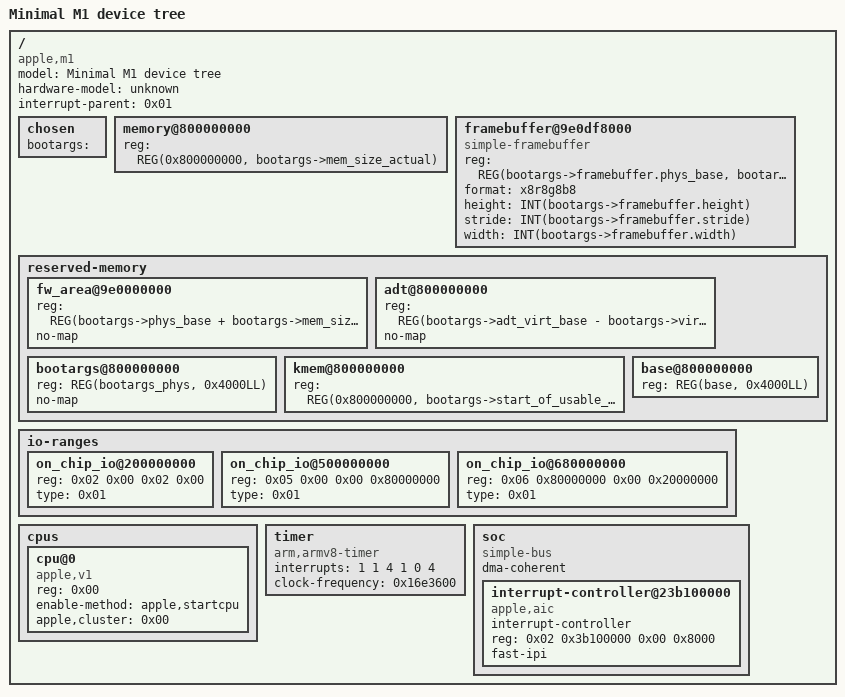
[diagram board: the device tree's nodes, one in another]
#define REG(x,y) <${cpu_to_be32((x)>>32)} \
	          ${cpu_to_be32((x)&U32_MAX)} \
		  ${cpu_to_be32((y)>>32)} \
		  ${cpu_to_be32((y)&U32_MAX)}>

#define INT(x) <${cpu_to_be32(x)}>

/dts-v1/;

/ {
	model = "Minimal M1 device tree";
	compatible = "apple,m1";
	hardware-model = "unknown";
	interrupt-parent = <0x01>;
	#address-cells = <0x02>;
	#size-cells = <0x02>;

	chosen {
		bootargs = "";
	};

	memory@800000000 {
		device_type = "memory";
		reg = REG(0x800000000, bootargs->mem_size_actual);
	};

	framebuffer@9e0df8000 {
		#address-cells = <0x02>;
		#size-cells = <0x02>;
		compatible = "simple-framebuffer";
		reg = REG(bootargs->framebuffer.phys_base,
		          bootargs->framebuffer.stride *
			  bootargs->framebuffer.height);
		format = "x8r8g8b8";
		height = INT(bootargs->framebuffer.height);
		stride = INT(bootargs->framebuffer.stride);
		width = INT(bootargs->framebuffer.width);
		status = "okay";
	};

	/* Technically, these areas shouldn't overlap. */
	reserved-memory {
		#address-cells = <0x02>;
		#size-cells = <0x02>;
		ranges;

		/* The area at the end of memory. Not actually at 9e0000000
		 * on most machines. */
		fw_area@9e0000000 {
		        reg = REG(bootargs->phys_base
			          + bootargs->mem_size,
				  bootargs->mem_size_actual
				  - bootargs->mem_size
				  - bootargs->phys_base
				  + 0x800000000);
			no-map;
		};

		/* The Apple Device tree. */
		adt@800000000 {
			reg = REG(bootargs->adt_virt_base
			          - bootargs->virt_base
				  + bootargs->phys_base,
				  (u64)bootargs->adt_size);
			no-map;
		};

		/* The bootargs structure. */
		bootargs@800000000 {
			reg = REG(bootargs_phys, 0x4000LL);
			no-map;
		};

		/* Other memory below the start of usable memory, currently
		 * including the original kernel .macho. */
		kmem@800000000 {
			reg = REG(0x800000000,
			          bootargs->start_of_usable_memory
				  - 0x800000000);
		};

		/* The start of the macho header of the original kernel
		 * .macho */
		base@800000000 {
			reg = REG(base, 0x4000LL);
		};
	};

	io-ranges {
		#address-cells = <0x02>;
		#size-cells = <0x02>;
		ranges;

		on_chip_io@200000000 {
			reg = <0x02 0x00 0x02 0x00>;
			type = <0x01>;
		};

		on_chip_io@500000000 {
			reg = <0x05 0x00 0x00 0x80000000>;
			type = <0x01>;
		};

		on_chip_io@680000000 {
			reg = <0x06 0x80000000 0x00 0x20000000>;
			type = <0x01>;
		};
	};

	cpus {
		#address-cells = <0x01>;
		#size-cells = <0x00>;

		cpu@0 {
			device_type = "cpu";
			compatible = "apple,v1";
			reg = <0x00>;
			enable-method = "apple,startcpu";
			apple,cluster = <0x00>;
		};
	};

	timer {
		compatible = "arm,armv8-timer";
		interrupts = <1 1 4 1 0 4>;
		clock-frequency = <0x16e3600>;
	};

	soc {
		compatible = "simple-bus";
		#address-cells = <0x02>;
		#size-cells = <0x02>;
		ranges;
		dma-coherent;

		/* You might think the minimal kernel does not require
		 * an interrupt controller, and you'd be right: in ARM
		 * terminology, the minimal kernel uses only FIQs, no *
		 * IRQs. However, FIQ handling is currently done in the
		 * AIC driver; it shouldn't be, and this shouldn't be
		 * here. */

		interrupt-controller@23b100000 {
			compatible = "apple,aic";
			#interrupt-cells = <0x03>;
			interrupt-controller;
			reg = <0x02 0x3b100000 0x00 0x8000>;
			fast-ipi;
			phandle = <0x01>;
		};
	};
};
